AUTOSAR XML (schema 4-2-2)
package /AUTOSAR_ComM/SwcImplementations
  swc implementation ComM_Imp: programming-language=C, sw-version=10.0.0, vendor-id=6, behavior=ComM_Int
    code-descriptors:
      code ComM_Imp_Code: artifact-descriptors=autosar-engineering-object={short-label=Code, category=SWSRC}
    resource consumption ResourceConsumption_ResourceConsumption
package /AUTOSAR_ComM/SwComponentTypes
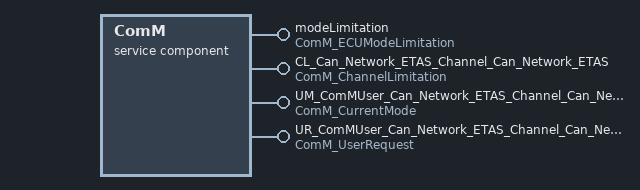
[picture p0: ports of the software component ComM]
  service sw component type ComM
    4 x provide port:
      modeLimitation: provided-interface=ComM_ECUModeLimitation
      CL_Can_Network_ETAS_Channel_Can_Network_ETAS: provided-interface=ComM_ChannelLimitation
      UM_ComMUser_Can_Network_ETAS_Channel_Can_Network_ETAS: mode-switch-sender-com-spec{mode-group=currentMode, queue-length=1}, provided-interface=ComM_CurrentMode
      UR_ComMUser_Can_Network_ETAS_Channel_Can_Network_ETAS: server-com-spec{operation=RequestComMode, queue-length=5}, provided-interface=ComM_UserRequest
    behavior ComM_Int: data-type-mapping=ComMModeMapping, handle-termination-and-restart=CAN-BE-TERMINATED-AND-RESTARTED
      10 x operation invoked event:
        OIE_UR_ComMUser_Can_Network_ETAS_Channel_Can_Network_ETAS_RequestComMode: start-on-event=RequestComMode, operation=UR_ComMUser_Can_Network_ETAS_Channel_Can_Network_ETAS.RequestComMode
        OIE_UR_ComMUser_Can_Network_ETAS_Channel_Can_Network_ETAS_GetRequestedComMode: start-on-event=GetRequestedComMode, operation=UR_ComMUser_Can_Network_ETAS_Channel_Can_Network_ETAS.GetRequestedComMode
        OIE_UR_ComMUser_Can_Network_ETAS_Channel_Can_Network_ETAS_GetCurrentComMode: start-on-event=GetCurrentComMode, operation=UR_ComMUser_Can_Network_ETAS_Channel_Can_Network_ETAS.GetCurrentComMode
        OIE_UR_ComMUser_Can_Network_ETAS_Channel_Can_Network_ETAS_GetMaxComMode: start-on-event=GetMaxComMode, operation=UR_ComMUser_Can_Network_ETAS_Channel_Can_Network_ETAS.GetMaxComMode
        OIE_ML_LimitECUToNoComMode: start-on-event=LimitECUToNoComMode, operation=modeLimitation.LimitECUToNoComMode
        OIE_ML_ReadInhibitCounter: start-on-event=ReadInhibitCounter, operation=modeLimitation.ReadInhibitCounter
        OIE_ML_ResetInhibitCounter: start-on-event=ResetInhibitCounter, operation=modeLimitation.ResetInhibitCounter
        OIE_ML_SetECUGroupClassification: start-on-event=SetECUGroupClassification, operation=modeLimitation.SetECUGroupClassification
        OIE_CL_Can_Network_ETAS_Channel_Can_Network_ETAS_LimitChannelToNoComMode: start-on-event=LimitChannelToNoComMode, operation=CL_Can_Network_ETAS_Channel_Can_Network_ETAS.LimitChannelToNoComMode
        OIE_CL_Can_Network_ETAS_Channel_Can_Network_ETAS_GetInhibitionStatus: start-on-event=GetInhibitionStatus, operation=CL_Can_Network_ETAS_Channel_Can_Network_ETAS.GetInhibitionStatus
      port-api-options:
        {enable-take-address=false, indirect-api=false, port-defined-argument-value{value=UR_ComMUser_Can_Network_ETAS_Channel_Can_Network_ETAS:0, value-type=ComM_UserHandleType}, port=UR_ComMUser_Can_Network_ETAS_Channel_Can_Network_ETAS}
        {enable-take-address=false, indirect-api=false, port-defined-argument-value{value=CL_Can_Network_ETAS_Channel_Can_Network_ETAS:0, value-type=NetworkHandleType}, port=CL_Can_Network_ETAS_Channel_Can_Network_ETAS}
      11 x runnable:
        LimitECUToNoComMode: runnable-entity-argument=symbol=Status, symbol=ComM_LimitECUToNoComMode
        ReadInhibitCounter: runnable-entity-argument=symbol=CounterValue, symbol=ComM_ReadInhibitCounter
        ResetInhibitCounter: symbol=ComM_ResetInhibitCounter
        SetECUGroupClassification: runnable-entity-argument=symbol=Status, symbol=ComM_SetECUGroupClassification
        LimitChannelToNoComMode: arguments=[symbol=Channel, symbol=Status], symbol=ComM_LimitChannelToNoComMode
        GetInhibitionStatus: arguments=[symbol=Channel, symbol=Status], symbol=ComM_GetInhibitionStatus
        RequestComMode: arguments=[symbol=User, symbol=ComMode], can-be-invoked-concurrently=true, symbol=ComM_RequestComMode
        MainFunction_Can_Network_ETAS_Channel_Can_Network_ETAS: symbol=ComM_MainFunction_Can_Network_ETAS_Channel_Can_Network_ETAS
        GetMaxComMode: arguments=[symbol=User, symbol=ComMode], can-be-invoked-concurrently=true, symbol=ComM_GetMaxComMode
        GetRequestedComMode: arguments=[symbol=User, symbol=ComMode], can-be-invoked-concurrently=true, symbol=ComM_GetRequestedComMode
        GetCurrentComMode: arguments=[symbol=User, symbol=ComMode], can-be-invoked-concurrently=true, symbol=ComM_GetCurrentComMode
          mode switch point MSP_ComM_User_ComMUser_Can_Network_ETAS_Channel_Can_Network_ETAS: mode-group=UM_ComMUser_Can_Network_ETAS_Channel_Can_Network_ETAS.currentMode
package /AUTOSAR_ComM/SwcBswMappings/SwcBswmapping
  swc bsw mapping SwcBswMapping_ComM: bsw-behavior=BswInternalBehavior, swc-bsw-runnable-mapping{bsw-entity=SE_MainFunction_Can_Network_ETAS_Channel_Can_Network_ETAS, swc-runnable=MainFunction_Can_Network_ETAS_Channel_Can_Network_ETAS}, swc-behavior=ComM_Int
